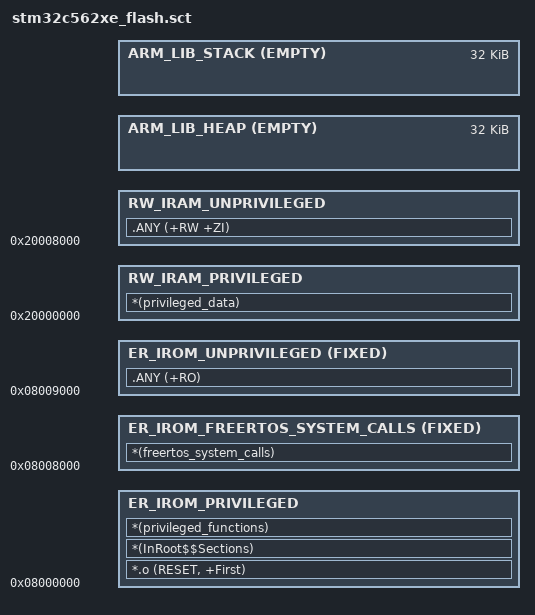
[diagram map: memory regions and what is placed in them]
#! armclang -E --target=arm-arm-none-eabi -mcpu=cortex-m33 -xc
; command above MUST be in first line (no comment above!)

; ******************************************************************************
; * @file    stm32c562xe_flash.sct
; * @brief   Linker File
; ******************************************************************************
; * @attention
; *
; * Copyright (c) 2026 STMicroelectronics.
; * All rights reserved.
; *
; * This software is licensed under terms that can be found in the LICENSE file
; * in the root directory of this software component.
; * If no LICENSE file comes with this software, it is provided AS-IS.
; *
; ******************************************************************************

#define __HEAP_SIZE 0x8000
#define __STACK_SIZE 0x8000

; Flash Layout
;
;  ---------------------
; |   Privileged Code   |
;  ---------------------
; |  Unprivileged Code  |
;  ---------------------
;
; RAM Layout
;
;  ---------------------
; |   Privileged Data   |
;  ---------------------
; |  Unprivileged Data  |
;  ---------------------

LR_APP 0x08000000 0x00200000 ; load region size_region
{
    ER_IROM_PRIVILEGED 0x08000000
    {
        *.o (RESET, +First)
        *(InRoot$$Sections)
        *(privileged_functions)
    }

    ER_IROM_FREERTOS_SYSTEM_CALLS 0x08008000 FIXED
    {
        *(freertos_system_calls)
    }

    ER_IROM_UNPRIVILEGED 0x08009000 FIXED
    {
        .ANY (+RO)
    }

    RW_IRAM_PRIVILEGED 0x20000000
    {
        *(privileged_data)
    }

    RW_IRAM_UNPRIVILEGED 0x20008000
    {
        .ANY (+RW +ZI)
    }

   ARM_LIB_HEAP AlignExpr(+0, 8) EMPTY  __HEAP_SIZE
   {
   }

   ARM_LIB_STACK AlignExpr(+0, 8) EMPTY  __STACK_SIZE
   {
   }
}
